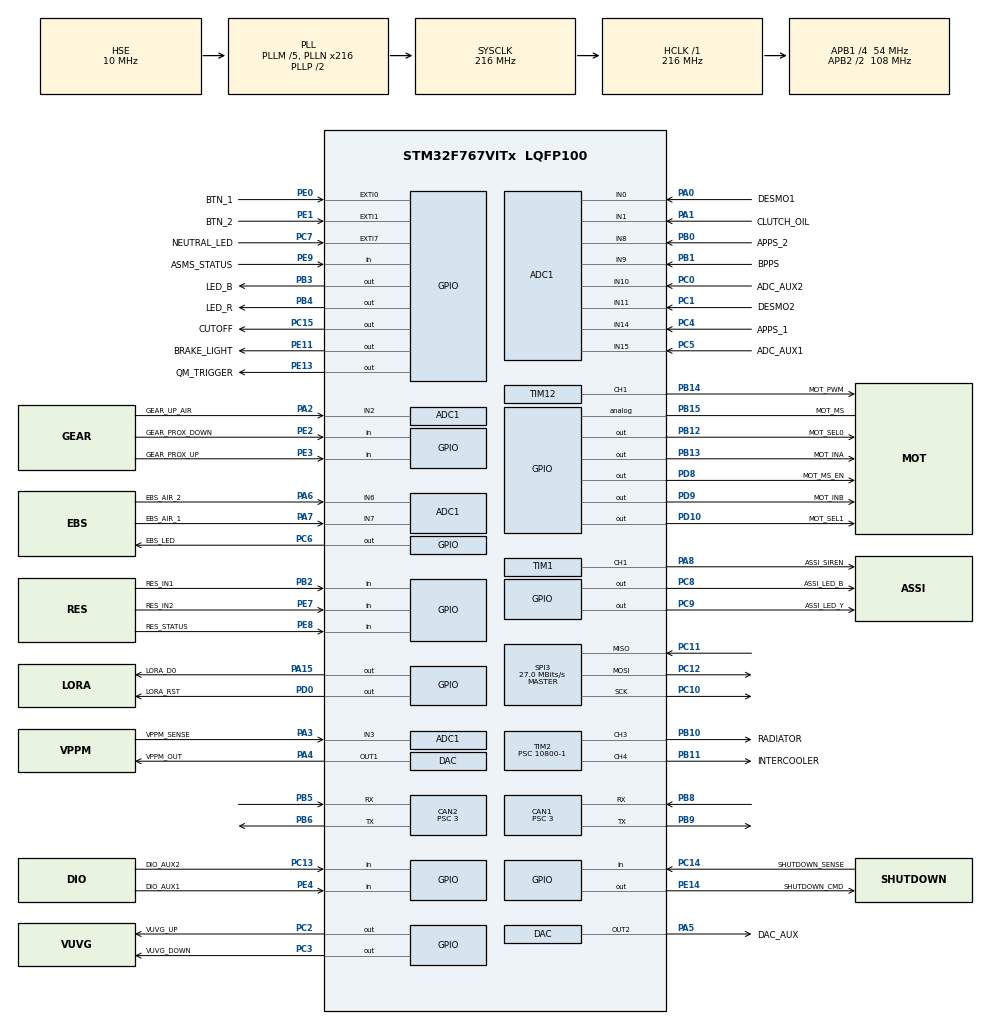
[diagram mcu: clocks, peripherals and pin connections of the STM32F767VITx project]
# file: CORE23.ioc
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ADC1.Channel-0\#ChannelRegularConversion=ADC_CHANNEL_0
ADC1.Channel-1\#ChannelRegularConversion=ADC_CHANNEL_1
ADC1.Channel-10\#ChannelRegularConversion=ADC_CHANNEL_14
ADC1.Channel-11\#ChannelRegularConversion=ADC_CHANNEL_15
ADC1.Channel-2\#ChannelRegularConversion=ADC_CHANNEL_2
ADC1.Channel-3\#ChannelRegularConversion=ADC_CHANNEL_3
ADC1.Channel-4\#ChannelRegularConversion=ADC_CHANNEL_6
ADC1.Channel-5\#ChannelRegularConversion=ADC_CHANNEL_7
ADC1.Channel-6\#ChannelRegularConversion=ADC_CHANNEL_8
ADC1.Channel-7\#ChannelRegularConversion=ADC_CHANNEL_9
ADC1.Channel-8\#ChannelRegularConversion=ADC_CHANNEL_10
ADC1.Channel-9\#ChannelRegularConversion=ADC_CHANNEL_11
ADC1.ContinuousConvMode=ENABLE
ADC1.DMAContinuousRequests=ENABLE
ADC1.EOCSelection=ADC_EOC_SINGLE_CONV
ADC1.NbrOfConversion=12
ADC1.NbrOfConversionFlag=1
ADC1.Rank-0\#ChannelRegularConversion=1
ADC1.Rank-1\#ChannelRegularConversion=2
ADC1.Rank-10\#ChannelRegularConversion=11
ADC1.Rank-11\#ChannelRegularConversion=12
ADC1.Rank-2\#ChannelRegularConversion=3
ADC1.Rank-3\#ChannelRegularConversion=4
ADC1.Rank-4\#ChannelRegularConversion=5
ADC1.Rank-5\#ChannelRegularConversion=6
ADC1.Rank-6\#ChannelRegularConversion=7
ADC1.Rank-7\#ChannelRegularConversion=8
ADC1.Rank-8\#ChannelRegularConversion=9
ADC1.Rank-9\#ChannelRegularConversion=10
ADC1.SamplingTime-0\#ChannelRegularConversion=ADC_SAMPLETIME_84CYCLES
ADC1.SamplingTime-1\#ChannelRegularConversion=ADC_SAMPLETIME_84CYCLES
ADC1.SamplingTime-10\#ChannelRegularConversion=ADC_SAMPLETIME_84CYCLES
ADC1.SamplingTime-11\#ChannelRegularConversion=ADC_SAMPLETIME_84CYCLES
ADC1.SamplingTime-2\#ChannelRegularConversion=ADC_SAMPLETIME_84CYCLES
ADC1.SamplingTime-3\#ChannelRegularConversion=ADC_SAMPLETIME_84CYCLES
ADC1.SamplingTime-4\#ChannelRegularConversion=ADC_SAMPLETIME_84CYCLES
ADC1.SamplingTime-5\#ChannelRegularConversion=ADC_SAMPLETIME_84CYCLES
ADC1.SamplingTime-6\#ChannelRegularConversion=ADC_SAMPLETIME_84CYCLES
ADC1.SamplingTime-7\#ChannelRegularConversion=ADC_SAMPLETIME_84CYCLES
ADC1.SamplingTime-8\#ChannelRegularConversion=ADC_SAMPLETIME_84CYCLES
ADC1.SamplingTime-9\#ChannelRegularConversion=ADC_SAMPLETIME_84CYCLES
ADC1.ScanConvMode=ADC_SCAN_ENABLE
ADC1.master=1
CAN1.BS1=CAN_BS1_15TQ
CAN1.BS2=CAN_BS2_2TQ
CAN1.CalculateBaudRate=1000000
CAN1.CalculateTimeBit=1000
CAN1.CalculateTimeQuantum=55.55555555555556
CAN1.Prescaler=3
CAN2.BS1=CAN_BS1_15TQ
CAN2.BS2=CAN_BS2_2TQ
CAN2.CalculateBaudRate=1000000
CAN2.CalculateTimeBit=1000
CAN2.CalculateTimeQuantum=55.55555555555556
CAN2.Prescaler=3
CAN2.RFLM=DISABLE
CAN2.SJW=CAN_SJW_1TQ
CORTEX_M7.CPU_DCache=Disabled
CORTEX_M7.CPU_ICache=Disabled
Dma.ADC1.0.Direction=DMA_PERIPH_TO_MEMORY
Dma.ADC1.0.FIFOMode=DMA_FIFOMODE_DISABLE
Dma.ADC1.0.Instance=DMA2_Stream0
Dma.ADC1.0.MemDataAlignment=DMA_MDATAALIGN_HALFWORD
Dma.ADC1.0.MemInc=DMA_MINC_ENABLE
Dma.ADC1.0.Mode=DMA_CIRCULAR
Dma.ADC1.0.PeriphDataAlignment=DMA_PDATAALIGN_HALFWORD
Dma.ADC1.0.PeriphInc=DMA_PINC_DISABLE
Dma.ADC1.0.Priority=DMA_PRIORITY_MEDIUM
Dma.Request0=ADC1
FREERTOS.Mutexes01=EngCanSem,Dynamic,NULL;ASCanSem,Dynamic,NULL;ADCSem,Dynamic,NULL;CanErrSem,Dynamic,NULL;ASBCheckSem,Dynamic,NULL
FREERTOS.Tasks01=FansContrTask,8,128,fansContrThread,As weak,NULL,Dynamic,NULL,NULL;DebugTask,8,128,debugThread,As weak,NULL,Dynamic,NULL,NULL;PedalTask,8,128,pedalThread,As weak,NULL,Dynamic,NULL,NULL;GearTask,8,128,gearThread,As weak,NULL,Dynamic,NULL,NULL;TelemetryTask,8,128,telemetryThread,As weak,NULL,Dynamic,NULL,NULL;ASAccTask,8,128,ASAccThread,As weak,NULL,Dynamic,NULL,NULL;ErrHandASTask,8,128,errorHandlerASThread,As weak,NULL,Dynamic,NULL,NULL;ASStateHandTask,8,128,ASStateHandlerThread,As weak,NULL,Dynamic,NULL,NULL;ASBCheckTask,8,128,ASBCheckThread,As weak,NULL,Dynamic,NULL,NULL;CheckModeTask,8,128,checkModeThread,As weak,NULL,Dynamic,NULL,NULL;CanHandlerTask,11,128,canHandlerThread,As weak,NULL,Dynamic,NULL,NULL;ADCTask,8,128,ADCThread,As weak,NULL,Dynamic,NULL,NULL
FREERTOS.configQUEUE_REGISTRY_SIZE=128
FREERTOS.configUSE_NEWLIB_REENTRANT=1
Mcu.Family=STM32F7
Mcu.Name=STM32F767VITx
Mcu.Package=LQFP100
NVIC.CAN1_RX0_IRQn=true\:5\:0\:false\:false\:true\:true\:true\:true\:true
NVIC.CAN2_RX1_IRQn=true\:5\:0\:false\:false\:true\:true\:true\:true\:true
NVIC.DMA2_Stream0_IRQn=true\:5\:0\:false\:false\:true\:true\:false\:true\:true
NVIC.EXTI0_IRQn=true\:5\:0\:false\:false\:true\:true\:true\:true\:true
NVIC.EXTI1_IRQn=true\:5\:0\:false\:false\:true\:true\:true\:true\:true
NVIC.EXTI9_5_IRQn=true\:5\:0\:false\:false\:true\:true\:true\:true\:true
NVIC.PriorityGroup=NVIC_PRIORITYGROUP_4
NVIC.TIM6_DAC_IRQn=true\:15\:0\:false\:false\:true\:false\:false\:true\:true
NVIC.TimeBase=TIM6_DAC_IRQn
NVIC.TimeBaseIP=TIM6
PA0/WKUP.GPIO_Label=DESMO1
PA0/WKUP.Signal=ADCx_IN0
PA1.GPIO_Label=CLUTCH_OIL
PA1.Signal=ADCx_IN1
PA13.Mode=Serial_Wire
PA13.Signal=SYS_JTMS-SWDIO
PA14.Mode=Serial_Wire
PA14.Signal=SYS_JTCK-SWCLK
PA15.GPIO_Label=LORA_D0
PA15.Signal=GPIO_Output
PA2.GPIO_Label=GEAR_UP_AIR
PA2.Signal=ADCx_IN2
PA3.GPIO_Label=VPPM_SENSE
PA3.Signal=ADCx_IN3
PA4.GPIO_Label=VPPM_OUT
PA4.Signal=COMP_DAC1_group
PA5.GPIO_Label=DAC_AUX
PA5.Signal=COMP_DAC2_group
PA6.GPIO_Label=EBS_AIR_2
PA6.Signal=ADCx_IN6
PA7.GPIO_Label=EBS_AIR_1
PA7.Signal=ADCx_IN7
PA8.GPIO_Label=ASSI_SIREN
PA8.Signal=S_TIM1_CH1
PB0.GPIO_Label=APPS_2
PB0.Signal=ADCx_IN8
PB1.GPIO_Label=BPPS
PB1.Signal=ADCx_IN9
PB10.GPIO_Label=RADIATOR
PB10.Signal=S_TIM2_CH3
PB11.GPIO_Label=INTERCOOLER
PB11.Signal=S_TIM2_CH4
PB12.GPIO_Label=MOT_SEL0
PB12.Signal=GPIO_Output
PB13.GPIO_Label=MOT_INA
PB13.Signal=GPIO_Output
PB14.GPIO_Label=MOT_PWM
PB14.Signal=S_TIM12_CH1
PB15.GPIO_Label=MOT_MS
PB15.Signal=GPIO_Analog
PB2.GPIO_Label=RES_IN1
PB2.Signal=GPIO_Input
PB3.GPIO_Label=LED_B
PB3.Signal=GPIO_Output
PB4.GPIO_Label=LED_R
PB4.Signal=GPIO_Output
PB5.Mode=CAN_Activate
PB5.Signal=CAN2_RX
PB6.Mode=CAN_Activate
PB6.Signal=CAN2_TX
PB8.Mode=CAN_Activate
PB8.Signal=CAN1_RX
PB9.Mode=CAN_Activate
PB9.Signal=CAN1_TX
PC0.GPIO_Label=ADC_AUX2
PC0.Signal=ADCx_IN10
PC1.GPIO_Label=DESMO2
PC1.Signal=ADCx_IN11
PC10.Mode=Full_Duplex_Master
PC10.Signal=SPI3_SCK
PC11.Mode=Full_Duplex_Master
PC11.Signal=SPI3_MISO
PC12.Mode=Full_Duplex_Master
PC12.Signal=SPI3_MOSI
PC13.GPIO_Label=DIO_AUX2
PC13.Signal=GPIO_Input
PC14/OSC32_IN.GPIO_Label=SHUTDOWN_SENSE
PC14/OSC32_IN.Signal=GPIO_Input
PC15/OSC32_OUT.GPIO_Label=CUTOFF
PC15/OSC32_OUT.Signal=GPIO_Output
PC2.GPIO_Label=VUVG_UP
PC2.Signal=GPIO_Output
PC3.GPIO_Label=VUVG_DOWN
PC3.Signal=GPIO_Output
PC4.GPIO_Label=APPS_1
PC4.Signal=ADCx_IN14
PC5.GPIO_Label=ADC_AUX1
PC5.Signal=ADCx_IN15
PC6.GPIO_Label=EBS_LED
PC6.Signal=GPIO_Output
PC7.GPIO_Label=NEUTRAL_LED
PC7.Signal=GPXTI7
PC8.GPIO_Label=ASSI_LED_B
PC8.Signal=GPIO_Output
PC9.GPIO_Label=ASSI_LED_Y
PC9.Signal=GPIO_Output
PD0.GPIO_Label=LORA_RST
PD0.Signal=GPIO_Output
PD10.GPIO_Label=MOT_SEL1
PD10.Signal=GPIO_Output
PD8.GPIO_Label=MOT_MS_EN
PD8.Signal=GPIO_Output
PD9.GPIO_Label=MOT_INB
PD9.Signal=GPIO_Output
PE0.GPIO_Label=BTN_1
PE0.GPIO_PuPd=GPIO_PULLDOWN
PE0.Signal=GPXTI0
PE1.GPIO_Label=BTN_2
PE1.GPIO_PuPd=GPIO_PULLDOWN
PE1.Signal=GPXTI1
PE11.GPIO_Label=BRAKE_LIGHT
PE11.Signal=GPIO_Output
PE13.GPIO_Label=QM_TRIGGER
PE13.GPIO_ModeDefaultOutputPP=GPIO_MODE_OUTPUT_PP
PE13.Signal=GPIO_Output
PE14.GPIO_Label=SHUTDOWN_CMD
PE14.Signal=GPIO_Output
PE2.GPIO_Label=GEAR_PROX_DOWN
PE2.Signal=GPIO_Input
PE3.GPIO_Label=GEAR_PROX_UP
PE3.Signal=GPIO_Input
PE4.GPIO_Label=DIO_AUX1
PE4.Signal=GPIO_Input
PE7.GPIO_Label=RES_IN2
PE7.Signal=GPIO_Input
PE8.GPIO_Label=RES_STATUS
PE8.Signal=GPIO_Input
PE9.GPIO_Label=ASMS_STATUS
PE9.Signal=GPIO_Input
PH0/OSC_IN.Mode=HSE-External-Oscillator
PH0/OSC_IN.Signal=RCC_OSC_IN
PH1/OSC_OUT.Mode=HSE-External-Oscillator
PH1/OSC_OUT.Signal=RCC_OSC_OUT
ProjectManager.HeapSize=0x200
ProjectManager.StackSize=0x400
ProjectManager.TargetToolchain=Makefile
RCC.AHBFreq_Value=216000000
RCC.APB1CLKDivider=RCC_HCLK_DIV4
RCC.APB1Freq_Value=54000000
RCC.APB1TimFreq_Value=108000000
RCC.APB2CLKDivider=RCC_HCLK_DIV2
RCC.APB2Freq_Value=108000000
RCC.APB2TimFreq_Value=216000000
RCC.CortexFreq_Value=216000000
RCC.HCLKFreq_Value=216000000
RCC.HSE_VALUE=10000000
RCC.HSI_VALUE=16000000
RCC.LSE_VALUE=32768
RCC.PLLM=5
RCC.PLLN=216
RCC.PLLSourceVirtual=RCC_PLLSOURCE_HSE
RCC.SYSCLKFreq_VALUE=216000000
RCC.SYSCLKSource=RCC_SYSCLKSOURCE_PLLCLK
RCC.USBFreq_Value=216000000
RCC.VCOOutputFreq_Value=432000000
SH.ADCx_IN0.0=ADC1_IN0,IN0
SH.ADCx_IN1.0=ADC1_IN1,IN1
SH.ADCx_IN10.0=ADC1_IN10,IN10
SH.ADCx_IN11.0=ADC1_IN11,IN11
SH.ADCx_IN14.0=ADC1_IN14,IN14
SH.ADCx_IN15.0=ADC1_IN15,IN15
SH.ADCx_IN2.0=ADC1_IN2,IN2
SH.ADCx_IN3.0=ADC1_IN3,IN3
SH.ADCx_IN6.0=ADC1_IN6,IN6
SH.ADCx_IN7.0=ADC1_IN7,IN7
SH.ADCx_IN8.0=ADC1_IN8,IN8
SH.ADCx_IN9.0=ADC1_IN9,IN9
SH.COMP_DAC1_group.0=DAC_OUT1,DAC_OUT1
SH.COMP_DAC2_group.0=DAC_OUT2,DAC_OUT2
SH.S_TIM12_CH1.0=TIM12_CH1,PWM Generation1 CH1
SH.S_TIM1_CH1.0=TIM1_CH1,PWM Generation1 CH1
SH.S_TIM2_CH3.0=TIM2_CH3,PWM Generation3 CH3
SH.S_TIM2_CH4.0=TIM2_CH4,PWM Generation4 CH4
SPI3.CalculateBaudRate=27.0 MBits/s
SPI3.Direction=SPI_DIRECTION_2LINES
SPI3.Mode=SPI_MODE_MASTER
SPI3.VirtualType=VM_MASTER
TIM1.Channel-PWM\ Generation1\ CH1=TIM_CHANNEL_1
TIM1.Period=100-1
TIM1.Prescaler=10800-1
TIM1.Pulse-PWM\ Generation1\ CH1=15
TIM12.Channel-PWM\ Generation1\ CH1=TIM_CHANNEL_1
TIM2.Channel-PWM\ Generation3\ CH3=TIM_CHANNEL_3
TIM2.Channel-PWM\ Generation4\ CH4=TIM_CHANNEL_4
TIM2.OCPolarity_3=TIM_OCPOLARITY_LOW
TIM2.OCPolarity_4=TIM_OCPOLARITY_LOW
TIM2.Period=100-1
TIM2.Prescaler=10800-1
TIM2.Pulse-PWM\ Generation3\ CH3=15
TIM2.Pulse-PWM\ Generation4\ CH4=15
TIM5.Prescaler=108
VP_FREERTOS_VS_CMSIS_V2.Mode=CMSIS_V2
VP_SYS_VS_tim6.Mode=TIM6
VP_TIM1_VS_ClockSourceINT.Mode=Internal
VP_TIM2_VS_ClockSourceINT.Mode=Internal
VP_TIM3_VS_ClockSourceINT.Mode=Internal
VP_TIM5_VS_ClockSourceINT.Mode=Internal
board=custom

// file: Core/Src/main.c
/* USER CODE BEGIN Header */
/**
  ******************************************************************************
  * @file           : main.c
  * @brief          : Main program body
  ******************************************************************************
  * @attention
  *
  * Copyright (c) 2024 STMicroelectronics.
  * All rights reserved.
  *
  * This software is licensed under terms that can be found in the LICENSE file
  * in the root directory of this software component.
  * If no LICENSE file comes with this software, it is provided AS-IS.
  *
  ******************************************************************************
  */
/* USER CODE END Header */
#include "main.h"
#include "cmsis_os.h"

ADC_HandleTypeDef hadc1;
DMA_HandleTypeDef hdma_adc1;

CAN_HandleTypeDef hcan1;
CAN_HandleTypeDef hcan2;

DAC_HandleTypeDef hdac;

SPI_HandleTypeDef hspi3;

TIM_HandleTypeDef htim1;
TIM_HandleTypeDef htim2;
TIM_HandleTypeDef htim3;
TIM_HandleTypeDef htim5;
TIM_HandleTypeDef htim12;

/* Definitions for FansContrTask */
osThreadId_t FansContrTaskHandle;
const osThreadAttr_t FansContrTask_attributes = {
  .name = "FansContrTask",
  .stack_size = 128 * 4,
  .priority = (osPriority_t) osPriorityLow,
};
/* Definitions for DebugTask */
osThreadId_t DebugTaskHandle;
const osThreadAttr_t DebugTask_attributes = {
  .name = "DebugTask",
  .stack_size = 128 * 4,
  .priority = (osPriority_t) osPriorityLow,
};
/* Definitions for PedalTask */
osThreadId_t PedalTaskHandle;
const osThreadAttr_t PedalTask_attributes = {
  .name = "PedalTask",
  .stack_size = 128 * 4,
  .priority = (osPriority_t) osPriorityLow,
};
/* Definitions for GearTask */
osThreadId_t GearTaskHandle;
const osThreadAttr_t GearTask_attributes = {
  .name = "GearTask",
  .stack_size = 128 * 4,
  .priority = (osPriority_t) osPriorityLow,
};
/* Definitions for TelemetryTask */
osThreadId_t TelemetryTaskHandle;
const osThreadAttr_t TelemetryTask_attributes = {
  .name = "TelemetryTask",
  .stack_size = 128 * 4,
  .priority = (osPriority_t) osPriorityLow,
};
/* Definitions for ASAccTask */
osThreadId_t ASAccTaskHandle;
const osThreadAttr_t ASAccTask_attributes = {
  .name = "ASAccTask",
  .stack_size = 128 * 4,
  .priority = (osPriority_t) osPriorityLow,
};
/* Definitions for ErrHandASTask */
osThreadId_t ErrHandASTaskHandle;
const osThreadAttr_t ErrHandASTask_attributes = {
  .name = "ErrHandASTask",
  .stack_size = 128 * 4,
  .priority = (osPriority_t) osPriorityLow,
};
/* Definitions for ASStateHandTask */
osThreadId_t ASStateHandTaskHandle;
const osThreadAttr_t ASStateHandTask_attributes = {
  .name = "ASStateHandTask",
  .stack_size = 128 * 4,
  .priority = (osPriority_t) osPriorityLow,
};
/* Definitions for ASBCheckTask */
osThreadId_t ASBCheckTaskHandle;
const osThreadAttr_t ASBCheckTask_attributes = {
  .name = "ASBCheckTask",
  .stack_size = 128 * 4,
  .priority = (osPriority_t) osPriorityLow,
};
/* Definitions for CheckModeTask */
osThreadId_t CheckModeTaskHandle;
const osThreadAttr_t CheckModeTask_attributes = {
  .name = "CheckModeTask",
  .stack_size = 128 * 4,
  .priority = (osPriority_t) osPriorityLow,
};
/* Definitions for CanHandlerTask */
osThreadId_t CanHandlerTaskHandle;
const osThreadAttr_t CanHandlerTask_attributes = {
  .name = "CanHandlerTask",
  .stack_size = 128 * 4,
  .priority = (osPriority_t) osPriorityLow3,
};
/* Definitions for ADCTask */
osThreadId_t ADCTaskHandle;
const osThreadAttr_t ADCTask_attributes = {
  .name = "ADCTask",
  .stack_size = 128 * 4,
  .priority = (osPriority_t) osPriorityLow,
};
/* Definitions for EngCanSem */
osMutexId_t EngCanSemHandle;
const osMutexAttr_t EngCanSem_attributes = {
  .name = "EngCanSem"
};
/* Definitions for ASCanSem */
osMutexId_t ASCanSemHandle;
const osMutexAttr_t ASCanSem_attributes = {
  .name = "ASCanSem"
};
/* Definitions for ADCSem */
osMutexId_t ADCSemHandle;
const osMutexAttr_t ADCSem_attributes = {
  .name = "ADCSem"
};
/* Definitions for CanErrSem */
osMutexId_t CanErrSemHandle;
const osMutexAttr_t CanErrSem_attributes = {
  .name = "CanErrSem"
};
/* Definitions for ASBCheckSem */
osMutexId_t ASBCheckSemHandle;
const osMutexAttr_t ASBCheckSem_attributes = {
  .name = "ASBCheckSem"
};

void SystemClock_Config(void);
static void MX_GPIO_Init(void);
static void MX_DMA_Init(void);
static void MX_CAN1_Init(void);
static void MX_CAN2_Init(void);
static void MX_DAC_Init(void);
static void MX_SPI3_Init(void);
static void MX_TIM1_Init(void);
static void MX_TIM2_Init(void);
static void MX_TIM3_Init(void);
static void MX_TIM12_Init(void);
static void MX_ADC1_Init(void);
static void MX_TIM5_Init(void);
void fansContrThread(void *argument);
void debugThread(void *argument);
void pedalThread(void *argument);
void gearThread(void *argument);
void telemetryThread(void *argument);
void ASAccThread(void *argument);
void errorHandlerASThread(void *argument);
void ASStateHandlerThread(void *argument);
void ASBCheckThread(void *argument);
void checkModeThread(void *argument);
void canHandlerThread(void *argument);
void ADCThread(void *argument);

int main(void)
{

  /* MCU Configuration--------------------------------------------------------*/

  /* Reset of all peripherals, Initializes the Flash interface and the Systick. */
  HAL_Init();

  /* Configure the system clock */
  SystemClock_Config();

  /* Initialize all configured peripherals */
  MX_GPIO_Init();
  MX_DMA_Init();
  MX_CAN1_Init();
  MX_CAN2_Init();
  MX_DAC_Init();
  MX_SPI3_Init();
  MX_TIM1_Init();
  MX_TIM2_Init();
  MX_TIM3_Init();
  MX_TIM12_Init();
  MX_ADC1_Init();
  MX_TIM5_Init();

  /* Init scheduler */
  osKernelInitialize();
  /* Create the mutex(es) */
  /* creation of EngCanSem */
  EngCanSemHandle = osMutexNew(&EngCanSem_attributes);

  /* creation of ASCanSem */
  ASCanSemHandle = osMutexNew(&ASCanSem_attributes);

  /* creation of ADCSem */
  ADCSemHandle = osMutexNew(&ADCSem_attributes);

  /* creation of CanErrSem */
  CanErrSemHandle = osMutexNew(&CanErrSem_attributes);

  /* creation of ASBCheckSem */
  ASBCheckSemHandle = osMutexNew(&ASBCheckSem_attributes);

  /* Create the thread(s) */
  /* creation of FansContrTask */
  FansContrTaskHandle = osThreadNew(fansContrThread, NULL, &FansContrTask_attributes);

  /* creation of DebugTask */
  DebugTaskHandle = osThreadNew(debugThread, NULL, &DebugTask_attributes);

  /* creation of PedalTask */
  PedalTaskHandle = osThreadNew(pedalThread, NULL, &PedalTask_attributes);

  /* creation of GearTask */
  GearTaskHandle = osThreadNew(gearThread, NULL, &GearTask_attributes);

  /* creation of TelemetryTask */
  TelemetryTaskHandle = osThreadNew(telemetryThread, NULL, &TelemetryTask_attributes);

  /* creation of ASAccTask */
  ASAccTaskHandle = osThreadNew(ASAccThread, NULL, &ASAccTask_attributes);

  /* creation of ErrHandASTask */
  ErrHandASTaskHandle = osThreadNew(errorHandlerASThread, NULL, &ErrHandASTask_attributes);

  /* creation of ASStateHandTask */
  ASStateHandTaskHandle = osThreadNew(ASStateHandlerThread, NULL, &ASStateHandTask_attributes);

  /* creation of ASBCheckTask */
  ASBCheckTaskHandle = osThreadNew(ASBCheckThread, NULL, &ASBCheckTask_attributes);

  /* creation of CheckModeTask */
  CheckModeTaskHandle = osThreadNew(checkModeThread, NULL, &CheckModeTask_attributes);

  /* creation of CanHandlerTask */
  CanHandlerTaskHandle = osThreadNew(canHandlerThread, NULL, &CanHandlerTask_attributes);

  /* creation of ADCTask */
  ADCTaskHandle = osThreadNew(ADCThread, NULL, &ADCTask_attributes);

  /* USER CODE BEGIN RTOS_THREADS */
  /* add threads, ... */
  // Always before kernel start, shutdown CMD should be always on
  HAL_GPIO_WritePin(SHUTDOWN_CMD_GPIO_Port, SHUTDOWN_CMD_Pin, SET);

  vTaskSuspend(ASStateHandTaskHandle);
  vTaskSuspend(ASBCheckTaskHandle);
  vTaskSuspend(TelemetryTaskHandle);
  vTaskSuspend(ErrHandASTaskHandle);
  vTaskSuspend(PedalTaskHandle);
  vTaskSuspend(GearTaskHandle);

  /* USER CODE END RTOS_THREADS */

  /* Start scheduler */
  osKernelStart();

  /* We should never get here as control is now taken by the scheduler */
  /* Infinite loop */
  while (1)
  {

  }
}

void SystemClock_Config(void)
{
  RCC_OscInitTypeDef RCC_OscInitStruct = {0};
  RCC_ClkInitTypeDef RCC_ClkInitStruct = {0};

  /** Configure the main internal regulator output voltage
  */
  __HAL_RCC_PWR_CLK_ENABLE();
  __HAL_PWR_VOLTAGESCALING_CONFIG(PWR_REGULATOR_VOLTAGE_SCALE1);

  /** Initializes the RCC Oscillators according to the specified parameters
  * in the RCC_OscInitTypeDef structure.
  */
  RCC_OscInitStruct.OscillatorType = RCC_OSCILLATORTYPE_HSE;
  RCC_OscInitStruct.HSEState = RCC_HSE_ON;
  RCC_OscInitStruct.PLL.PLLState = RCC_PLL_ON;
  RCC_OscInitStruct.PLL.PLLSource = RCC_PLLSOURCE_HSE;
  RCC_OscInitStruct.PLL.PLLM = 5;
  RCC_OscInitStruct.PLL.PLLN = 216;
  RCC_OscInitStruct.PLL.PLLP = RCC_PLLP_DIV2;
  RCC_OscInitStruct.PLL.PLLQ = 2;
  RCC_OscInitStruct.PLL.PLLR = 2;
  if (HAL_RCC_OscConfig(&RCC_OscInitStruct) != HAL_OK)
  {
    Error_Handler();
  }

  /** Activate the Over-Drive mode
  */
  if (HAL_PWREx_EnableOverDrive() != HAL_OK)
  {
    Error_Handler();
  }

  /** Initializes the CPU, AHB and APB buses clocks
  */
  RCC_ClkInitStruct.ClockType = RCC_CLOCKTYPE_HCLK|RCC_CLOCKTYPE_SYSCLK
                              |RCC_CLOCKTYPE_PCLK1|RCC_CLOCKTYPE_PCLK2;
  RCC_ClkInitStruct.SYSCLKSource = RCC_SYSCLKSOURCE_PLLCLK;
  RCC_ClkInitStruct.AHBCLKDivider = RCC_SYSCLK_DIV1;
  RCC_ClkInitStruct.APB1CLKDivider = RCC_HCLK_DIV4;
  RCC_ClkInitStruct.APB2CLKDivider = RCC_HCLK_DIV2;

  if (HAL_RCC_ClockConfig(&RCC_ClkInitStruct, FLASH_LATENCY_7) != HAL_OK)
  {
    Error_Handler();
  }
}

static void MX_ADC1_Init(void)
{

  ADC_ChannelConfTypeDef sConfig = {0};

  /** Configure the global features of the ADC (Clock, Resolution, Data Alignment and number of conversion)
  */
  hadc1.Instance = ADC1;
  hadc1.Init.ClockPrescaler = ADC_CLOCK_SYNC_PCLK_DIV4;
  hadc1.Init.Resolution = ADC_RESOLUTION_12B;
  hadc1.Init.ScanConvMode = ADC_SCAN_ENABLE;
  hadc1.Init.ContinuousConvMode = ENABLE;
  hadc1.Init.DiscontinuousConvMode = DISABLE;
  hadc1.Init.ExternalTrigConvEdge = ADC_EXTERNALTRIGCONVEDGE_NONE;
  hadc1.Init.ExternalTrigConv = ADC_SOFTWARE_START;
  hadc1.Init.DataAlign = ADC_DATAALIGN_RIGHT;
  hadc1.Init.NbrOfConversion = 12;
  hadc1.Init.DMAContinuousRequests = ENABLE;
  hadc1.Init.EOCSelection = ADC_EOC_SINGLE_CONV;
  if (HAL_ADC_Init(&hadc1) != HAL_OK)
  {
    Error_Handler();
  }

  /** Configure for the selected ADC regular channel its corresponding rank in the sequencer and its sample time.
  */
  sConfig.Channel = ADC_CHANNEL_0;
  sConfig.Rank = ADC_REGULAR_RANK_1;
  sConfig.SamplingTime = ADC_SAMPLETIME_84CYCLES;
  if (HAL_ADC_ConfigChannel(&hadc1, &sConfig) != HAL_OK)
  {
    Error_Handler();
  }

  /** Configure for the selected ADC regular channel its corresponding rank in the sequencer and its sample time.
  */
  sConfig.Channel = ADC_CHANNEL_1;
  sConfig.Rank = ADC_REGULAR_RANK_2;
  if (HAL_ADC_ConfigChannel(&hadc1, &sConfig) != HAL_OK)
  {
    Error_Handler();
  }

  /** Configure for the selected ADC regular channel its corresponding rank in the sequencer and its sample time.
  */
  sConfig.Channel = ADC_CHANNEL_2;
  sConfig.Rank = ADC_REGULAR_RANK_3;
  if (HAL_ADC_ConfigChannel(&hadc1, &sConfig) != HAL_OK)
  {
    Error_Handler();
  }

  /** Configure for the selected ADC regular channel its corresponding rank in the sequencer and its sample time.
  */
  sConfig.Channel = ADC_CHANNEL_3;
  sConfig.Rank = ADC_REGULAR_RANK_4;
  if (HAL_ADC_ConfigChannel(&hadc1, &sConfig) != HAL_OK)
  {
    Error_Handler();
  }

  /** Configure for the selected ADC regular channel its corresponding rank in the sequencer and its sample time.
  */
  sConfig.Channel = ADC_CHANNEL_6;
  sConfig.Rank = ADC_REGULAR_RANK_5;
  if (HAL_ADC_ConfigChannel(&hadc1, &sConfig) != HAL_OK)
  {
    Error_Handler();
  }

  /** Configure for the selected ADC regular channel its corresponding rank in the sequencer and its sample time.
  */
  sConfig.Channel = ADC_CHANNEL_7;
  sConfig.Rank = ADC_REGULAR_RANK_6;
  if (HAL_ADC_ConfigChannel(&hadc1, &sConfig) != HAL_OK)
  {
    Error_Handler();
  }

  /** Configure for the selected ADC regular channel its corresponding rank in the sequencer and its sample time.
  */
  sConfig.Channel = ADC_CHANNEL_8;
  sConfig.Rank = ADC_REGULAR_RANK_7;
  if (HAL_ADC_ConfigChannel(&hadc1, &sConfig) != HAL_OK)
  {
    Error_Handler();
  }

  /** Configure for the selected ADC regular channel its corresponding rank in the sequencer and its sample time.
  */
  sConfig.Channel = ADC_CHANNEL_9;
  sConfig.Rank = ADC_REGULAR_RANK_8;
  if (HAL_ADC_ConfigChannel(&hadc1, &sConfig) != HAL_OK)
  {
    Error_Handler();
  }

  /** Configure for the selected ADC regular channel its corresponding rank in the sequencer and its sample time.
  */
  sConfig.Channel = ADC_CHANNEL_10;
  sConfig.Rank = ADC_REGULAR_RANK_9;
  if (HAL_ADC_ConfigChannel(&hadc1, &sConfig) != HAL_OK)
  {
    Error_Handler();
  }

  /** Configure for the selected ADC regular channel its corresponding rank in the sequencer and its sample time.
  */
  sConfig.Channel = ADC_CHANNEL_11;
  sConfig.Rank = ADC_REGULAR_RANK_10;
  if (HAL_ADC_ConfigChannel(&hadc1, &sConfig) != HAL_OK)
  {
    Error_Handler();
  }

  /** Configure for the selected ADC regular channel its corresponding rank in the sequencer and its sample time.
  */
  sConfig.Channel = ADC_CHANNEL_14;
  sConfig.Rank = ADC_REGULAR_RANK_11;
  if (HAL_ADC_ConfigChannel(&hadc1, &sConfig) != HAL_OK)
  {
    Error_Handler();
  }

  /** Configure for the selected ADC regular channel its corresponding rank in the sequencer and its sample time.
  */
  sConfig.Channel = ADC_CHANNEL_15;
  sConfig.Rank = ADC_REGULAR_RANK_12;
  if (HAL_ADC_ConfigChannel(&hadc1, &sConfig) != HAL_OK)
  {
    Error_Handler();
  }

}

static void MX_CAN1_Init(void)
{

  hcan1.Instance = CAN1;
  hcan1.Init.Prescaler = 3;
  hcan1.Init.Mode = CAN_MODE_NORMAL;
  hcan1.Init.SyncJumpWidth = CAN_SJW_1TQ;
  hcan1.Init.TimeSeg1 = CAN_BS1_15TQ;
  hcan1.Init.TimeSeg2 = CAN_BS2_2TQ;
  hcan1.Init.TimeTriggeredMode = DISABLE;
  hcan1.Init.AutoBusOff = DISABLE;
  hcan1.Init.AutoWakeUp = DISABLE;
  hcan1.Init.AutoRetransmission = DISABLE;
  hcan1.Init.ReceiveFifoLocked = DISABLE;
  hcan1.Init.TransmitFifoPriority = DISABLE;
  if (HAL_CAN_Init(&hcan1) != HAL_OK)
  {
    Error_Handler();
  }

}

static void MX_CAN2_Init(void)
{

  hcan2.Instance = CAN2;
  hcan2.Init.Prescaler = 3;
  hcan2.Init.Mode = CAN_MODE_NORMAL;
  hcan2.Init.SyncJumpWidth = CAN_SJW_1TQ;
  hcan2.Init.TimeSeg1 = CAN_BS1_15TQ;
  hcan2.Init.TimeSeg2 = CAN_BS2_2TQ;
  hcan2.Init.TimeTriggeredMode = DISABLE;
  hcan2.Init.AutoBusOff = DISABLE;
  hcan2.Init.AutoWakeUp = DISABLE;
  hcan2.Init.AutoRetransmission = DISABLE;
  hcan2.Init.ReceiveFifoLocked = DISABLE;
  hcan2.Init.TransmitFifoPriority = DISABLE;
  if (HAL_CAN_Init(&hcan2) != HAL_OK)
  {
    Error_Handler();
  }

}

static void MX_DAC_Init(void)
{

  DAC_ChannelConfTypeDef sConfig = {0};

  /** DAC Initialization
  */
  hdac.Instance = DAC;
  if (HAL_DAC_Init(&hdac) != HAL_OK)
  {
    Error_Handler();
  }

  /** DAC channel OUT1 config
  */
  sConfig.DAC_Trigger = DAC_TRIGGER_NONE;
  sConfig.DAC_OutputBuffer = DAC_OUTPUTBUFFER_ENABLE;
  if (HAL_DAC_ConfigChannel(&hdac, &sConfig, DAC_CHANNEL_1) != HAL_OK)
  {
    Error_Handler();
  }

  /** DAC channel OUT2 config
  */
  if (HAL_DAC_ConfigChannel(&hdac, &sConfig, DAC_CHANNEL_2) != HAL_OK)
  {
    Error_Handler();
  }

}

static void MX_SPI3_Init(void)
{

  /* SPI3 parameter configuration*/
  hspi3.Instance = SPI3;
  hspi3.Init.Mode = SPI_MODE_MASTER;
  hspi3.Init.Direction = SPI_DIRECTION_2LINES;
  hspi3.Init.DataSize = SPI_DATASIZE_4BIT;
  hspi3.Init.CLKPolarity = SPI_POLARITY_LOW;
  hspi3.Init.CLKPhase = SPI_PHASE_1EDGE;
  hspi3.Init.NSS = SPI_NSS_SOFT;
  hspi3.Init.BaudRatePrescaler = SPI_BAUDRATEPRESCALER_2;
  hspi3.Init.FirstBit = SPI_FIRSTBIT_MSB;
  hspi3.Init.TIMode = SPI_TIMODE_DISABLE;
  hspi3.Init.CRCCalculation = SPI_CRCCALCULATION_DISABLE;
  hspi3.Init.CRCPolynomial = 7;
  hspi3.Init.CRCLength = SPI_CRC_LENGTH_DATASIZE;
  hspi3.Init.NSSPMode = SPI_NSS_PULSE_ENABLE;
  if (HAL_SPI_Init(&hspi3) != HAL_OK)
  {
    Error_Handler();
  }

}

static void MX_TIM1_Init(void)
{

  TIM_ClockConfigTypeDef sClockSourceConfig = {0};
  TIM_MasterConfigTypeDef sMasterConfig = {0};
  TIM_OC_InitTypeDef sConfigOC = {0};
  TIM_BreakDeadTimeConfigTypeDef sBreakDeadTimeConfig = {0};

  htim1.Instance = TIM1;
  htim1.Init.Prescaler = 10800-1;
  htim1.Init.CounterMode = TIM_COUNTERMODE_UP;
  htim1.Init.Period = 100-1;
  htim1.Init.ClockDivision = TIM_CLOCKDIVISION_DIV1;
  htim1.Init.RepetitionCounter = 0;
  htim1.Init.AutoReloadPreload = TIM_AUTORELOAD_PRELOAD_DISABLE;
  if (HAL_TIM_Base_Init(&htim1) != HAL_OK)
  {
    Error_Handler();
  }
  sClockSourceConfig.ClockSource = TIM_CLOCKSOURCE_INTERNAL;
  if (HAL_TIM_ConfigClockSource(&htim1, &sClockSourceConfig) != HAL_OK)
  {
    Error_Handler();
  }
  if (HAL_TIM_PWM_Init(&htim1) != HAL_OK)
  {
    Error_Handler();
  }
  sMasterConfig.MasterOutputTrigger = TIM_TRGO_RESET;
  sMasterConfig.MasterOutputTrigger2 = TIM_TRGO2_RESET;
  sMasterConfig.MasterSlaveMode = TIM_MASTERSLAVEMODE_DISABLE;
  if (HAL_TIMEx_MasterConfigSynchronization(&htim1, &sMasterConfig) != HAL_OK)
  {
    Error_Handler();
  }
  sConfigOC.OCMode = TIM_OCMODE_PWM1;
  sConfigOC.Pulse = 15;
  sConfigOC.OCPolarity = TIM_OCPOLARITY_HIGH;
  sConfigOC.OCNPolarity = TIM_OCNPOLARITY_HIGH;
  sConfigOC.OCFastMode = TIM_OCFAST_DISABLE;
  sConfigOC.OCIdleState = TIM_OCIDLESTATE_RESET;
  sConfigOC.OCNIdleState = TIM_OCNIDLESTATE_RESET;
  if (HAL_TIM_PWM_ConfigChannel(&htim1, &sConfigOC, TIM_CHANNEL_1) != HAL_OK)
  {
    Error_Handler();
  }
  sBreakDeadTimeConfig.OffStateRunMode = TIM_OSSR_DISABLE;
  sBreakDeadTimeConfig.OffStateIDLEMode = TIM_OSSI_DISABLE;
  sBreakDeadTimeConfig.LockLevel = TIM_LOCKLEVEL_OFF;
  sBreakDeadTimeConfig.DeadTime = 0;
  sBreakDeadTimeConfig.BreakState = TIM_BREAK_DISABLE;
  sBreakDeadTimeConfig.BreakPolarity = TIM_BREAKPOLARITY_HIGH;
  sBreakDeadTimeConfig.BreakFilter = 0;
  sBreakDeadTimeConfig.Break2State = TIM_BREAK2_DISABLE;
  sBreakDeadTimeConfig.Break2Polarity = TIM_BREAK2POLARITY_HIGH;
  sBreakDeadTimeConfig.Break2Filter = 0;
  sBreakDeadTimeConfig.AutomaticOutput = TIM_AUTOMATICOUTPUT_DISABLE;
  if (HAL_TIMEx_ConfigBreakDeadTime(&htim1, &sBreakDeadTimeConfig) != HAL_OK)
  {
    Error_Handler();
  }
  HAL_TIM_MspPostInit(&htim1);

}

static void MX_TIM2_Init(void)
{

  TIM_ClockConfigTypeDef sClockSourceConfig = {0};
  TIM_MasterConfigTypeDef sMasterConfig = {0};
  TIM_OC_InitTypeDef sConfigOC = {0};

  htim2.Instance = TIM2;
  htim2.Init.Prescaler = 10800-1;
  htim2.Init.CounterMode = TIM_COUNTERMODE_UP;
  htim2.Init.Period = 100-1;
  htim2.Init.ClockDivision = TIM_CLOCKDIVISION_DIV1;
  htim2.Init.AutoReloadPreload = TIM_AUTORELOAD_PRELOAD_DISABLE;
  if (HAL_TIM_Base_Init(&htim2) != HAL_OK)
  {
    Error_Handler();
  }
  sClockSourceConfig.ClockSource = TIM_CLOCKSOURCE_INTERNAL;
  if (HAL_TIM_ConfigClockSource(&htim2, &sClockSourceConfig) != HAL_OK)
  {
    Error_Handler();
  }
  if (HAL_TIM_PWM_Init(&htim2) != HAL_OK)
  {
    Error_Handler();
  }
  sMasterConfig.MasterOutputTrigger = TIM_TRGO_RESET;
  sMasterConfig.MasterSlaveMode = TIM_MASTERSLAVEMODE_DISABLE;
  if (HAL_TIMEx_MasterConfigSynchronization(&htim2, &sMasterConfig) != HAL_OK)
  {
    Error_Handler();
  }
  sConfigOC.OCMode = TIM_OCMODE_PWM1;
  sConfigOC.Pulse = 15;
  sConfigOC.OCPolarity = TIM_OCPOLARITY_LOW;
  sConfigOC.OCFastMode = TIM_OCFAST_DISABLE;
  if (HAL_TIM_PWM_ConfigChannel(&htim2, &sConfigOC, TIM_CHANNEL_3) != HAL_OK)
  {
    Error_Handler();
  }
  if (HAL_TIM_PWM_ConfigChannel(&htim2, &sConfigOC, TIM_CHANNEL_4) != HAL_OK)
  {
    Error_Handler();
  }
  HAL_TIM_MspPostInit(&htim2);

}

static void MX_TIM3_Init(void)
{

  TIM_ClockConfigTypeDef sClockSourceConfig = {0};
  TIM_MasterConfigTypeDef sMasterConfig = {0};

  htim3.Instance = TIM3;
  htim3.Init.Prescaler = 0;
  htim3.Init.CounterMode = TIM_COUNTERMODE_UP;
  htim3.Init.Period = 65535;
  htim3.Init.ClockDivision = TIM_CLOCKDIVISION_DIV1;
  htim3.Init.AutoReloadPreload = TIM_AUTORELOAD_PRELOAD_DISABLE;
  if (HAL_TIM_Base_Init(&htim3) != HAL_OK)
  {
    Error_Handler();
  }
  sClockSourceConfig.ClockSource = TIM_CLOCKSOURCE_INTERNAL;
  if (HAL_TIM_ConfigClockSource(&htim3, &sClockSourceConfig) != HAL_OK)
  {
    Error_Handler();
  }
  sMasterConfig.MasterOutputTrigger = TIM_TRGO_RESET;
  sMasterConfig.MasterSlaveMode = TIM_MASTERSLAVEMODE_DISABLE;
  if (HAL_TIMEx_MasterConfigSynchronization(&htim3, &sMasterConfig) != HAL_OK)
  {
    Error_Handler();
  }

}

static void MX_TIM5_Init(void)
{

  TIM_ClockConfigTypeDef sClockSourceConfig = {0};
  TIM_MasterConfigTypeDef sMasterConfig = {0};

  htim5.Instance = TIM5;
  htim5.Init.Prescaler = 108;
  htim5.Init.CounterMode = TIM_COUNTERMODE_UP;
  htim5.Init.Period = 4294967295;
  htim5.Init.ClockDivision = TIM_CLOCKDIVISION_DIV1;
  htim5.Init.AutoReloadPreload = TIM_AUTORELOAD_PRELOAD_DISABLE;
  if (HAL_TIM_Base_Init(&htim5) != HAL_OK)
  {
    Error_Handler();
  }
  sClockSourceConfig.ClockSource = TIM_CLOCKSOURCE_INTERNAL;
  if (HAL_TIM_ConfigClockSource(&htim5, &sClockSourceConfig) != HAL_OK)
  {
    Error_Handler();
  }
  sMasterConfig.MasterOutputTrigger = TIM_TRGO_RESET;
  sMasterConfig.MasterSlaveMode = TIM_MASTERSLAVEMODE_DISABLE;
  if (HAL_TIMEx_MasterConfigSynchronization(&htim5, &sMasterConfig) != HAL_OK)
  {
    Error_Handler();
  }

}

static void MX_TIM12_Init(void)
{

  TIM_OC_InitTypeDef sConfigOC = {0};

  htim12.Instance = TIM12;
  htim12.Init.Prescaler = 0;
  htim12.Init.CounterMode = TIM_COUNTERMODE_UP;
  htim12.Init.Period = 65535;
  htim12.Init.ClockDivision = TIM_CLOCKDIVISION_DIV1;
  htim12.Init.AutoReloadPreload = TIM_AUTORELOAD_PRELOAD_DISABLE;
  if (HAL_TIM_PWM_Init(&htim12) != HAL_OK)
  {
    Error_Handler();
  }
  sConfigOC.OCMode = TIM_OCMODE_PWM1;
  sConfigOC.Pulse = 0;
  sConfigOC.OCPolarity = TIM_OCPOLARITY_HIGH;
  sConfigOC.OCFastMode = TIM_OCFAST_DISABLE;
  if (HAL_TIM_PWM_ConfigChannel(&htim12, &sConfigOC, TIM_CHANNEL_1) != HAL_OK)
  {
    Error_Handler();
  }
  HAL_TIM_MspPostInit(&htim12);

}

static void MX_DMA_Init(void)
{

  /* DMA controller clock enable */
  __HAL_RCC_DMA2_CLK_ENABLE();

  /* DMA interrupt init */
  /* DMA2_Stream0_IRQn interrupt configuration */
  HAL_NVIC_SetPriority(DMA2_Stream0_IRQn, 5, 0);
  HAL_NVIC_EnableIRQ(DMA2_Stream0_IRQn);

}

static void MX_GPIO_Init(void)
{
  GPIO_InitTypeDef GPIO_InitStruct = {0};

  /* GPIO Ports Clock Enable */
  __HAL_RCC_GPIOE_CLK_ENABLE();
  __HAL_RCC_GPIOC_CLK_ENABLE();
  __HAL_RCC_GPIOH_CLK_ENABLE();
  __HAL_RCC_GPIOA_CLK_ENABLE();
  __HAL_RCC_GPIOB_CLK_ENABLE();
  __HAL_RCC_GPIOD_CLK_ENABLE();

  /*Configure GPIO pin Output Level */
  HAL_GPIO_WritePin(GPIOC, CUTOFF_Pin|VUVG_UP_Pin|VUVG_DOWN_Pin|EBS_LED_Pin
                          |ASSI_LED_B_Pin|ASSI_LED_Y_Pin, GPIO_PIN_RESET);

  /*Configure GPIO pin Output Level */
  HAL_GPIO_WritePin(GPIOE, BRAKE_LIGHT_Pin|QM_TRIGGER_Pin|SHUTDOWN_CMD_Pin, GPIO_PIN_RESET);

  /*Configure GPIO pin Output Level */
  HAL_GPIO_WritePin(GPIOB, MOT_SEL0_Pin|MOT_INA_Pin|LED_B_Pin|LED_R_Pin, GPIO_PIN_RESET);

  /*Configure GPIO pin Output Level */
  HAL_GPIO_WritePin(GPIOD, MOT_MS_EN_Pin|MOT_INB_Pin|MOT_SEL1_Pin|LORA_RST_Pin, GPIO_PIN_RESET);

  /*Configure GPIO pin Output Level */
  HAL_GPIO_WritePin(LORA_D0_GPIO_Port, LORA_D0_Pin, GPIO_PIN_RESET);

  /*Configure GPIO pins : GEAR_PROX_DOWN_Pin GEAR_PROX_UP_Pin DIO_AUX1_Pin RES_IN2_Pin
                           RES_STATUS_Pin ASMS_STATUS_Pin */
  GPIO_InitStruct.Pin = GEAR_PROX_DOWN_Pin|GEAR_PROX_UP_Pin|DIO_AUX1_Pin|RES_IN2_Pin
                          |RES_STATUS_Pin|ASMS_STATUS_Pin;
  GPIO_InitStruct.Mode = GPIO_MODE_INPUT;
  GPIO_InitStruct.Pull = GPIO_NOPULL;
  HAL_GPIO_Init(GPIOE, &GPIO_InitStruct);

  /*Configure GPIO pins : DIO_AUX2_Pin SHUTDOWN_SENSE_Pin */
  GPIO_InitStruct.Pin = DIO_AUX2_Pin|SHUTDOWN_SENSE_Pin;
  GPIO_InitStruct.Mode = GPIO_MODE_INPUT;
  GPIO_InitStruct.Pull = GPIO_NOPULL;
  HAL_GPIO_Init(GPIOC, &GPIO_InitStruct);

  /*Configure GPIO pins : CUTOFF_Pin VUVG_UP_Pin VUVG_DOWN_Pin EBS_LED_Pin
                           ASSI_LED_B_Pin ASSI_LED_Y_Pin */
  GPIO_InitStruct.Pin = CUTOFF_Pin|VUVG_UP_Pin|VUVG_DOWN_Pin|EBS_LED_Pin
                          |ASSI_LED_B_Pin|ASSI_LED_Y_Pin;
  GPIO_InitStruct.Mode = GPIO_MODE_OUTPUT_PP;
  GPIO_InitStruct.Pull = GPIO_NOPULL;
  GPIO_InitStruct.Speed = GPIO_SPEED_FREQ_LOW;
  HAL_GPIO_Init(GPIOC, &GPIO_InitStruct);

  /*Configure GPIO pin : RES_IN1_Pin */
  GPIO_InitStruct.Pin = RES_IN1_Pin;
  GPIO_InitStruct.Mode = GPIO_MODE_INPUT;
  GPIO_InitStruct.Pull = GPIO_NOPULL;
  HAL_GPIO_Init(RES_IN1_GPIO_Port, &GPIO_InitStruct);

  /*Configure GPIO pins : BRAKE_LIGHT_Pin QM_TRIGGER_Pin SHUTDOWN_CMD_Pin */
  GPIO_InitStruct.Pin = BRAKE_LIGHT_Pin|QM_TRIGGER_Pin|SHUTDOWN_CMD_Pin;
  GPIO_InitStruct.Mode = GPIO_MODE_OUTPUT_PP;
  GPIO_InitStruct.Pull = GPIO_NOPULL;
  GPIO_InitStruct.Speed = GPIO_SPEED_FREQ_LOW;
  HAL_GPIO_Init(GPIOE, &GPIO_InitStruct);

  /*Configure GPIO pins : MOT_SEL0_Pin MOT_INA_Pin LED_B_Pin LED_R_Pin */
  GPIO_InitStruct.Pin = MOT_SEL0_Pin|MOT_INA_Pin|LED_B_Pin|LED_R_Pin;
  GPIO_InitStruct.Mode = GPIO_MODE_OUTPUT_PP;
  GPIO_InitStruct.Pull = GPIO_NOPULL;
  GPIO_InitStruct.Speed = GPIO_SPEED_FREQ_LOW;
  HAL_GPIO_Init(GPIOB, &GPIO_InitStruct);

  /*Configure GPIO pin : MOT_MS_Pin */
  GPIO_InitStruct.Pin = MOT_MS_Pin;
  GPIO_InitStruct.Mode = GPIO_MODE_ANALOG;
  GPIO_InitStruct.Pull = GPIO_NOPULL;
  HAL_GPIO_Init(MOT_MS_GPIO_Port, &GPIO_InitStruct);

  /*Configure GPIO pins : MOT_MS_EN_Pin MOT_INB_Pin MOT_SEL1_Pin LORA_RST_Pin */
  GPIO_InitStruct.Pin = MOT_MS_EN_Pin|MOT_INB_Pin|MOT_SEL1_Pin|LORA_RST_Pin;
  GPIO_InitStruct.Mode = GPIO_MODE_OUTPUT_PP;
  GPIO_InitStruct.Pull = GPIO_NOPULL;
  GPIO_InitStruct.Speed = GPIO_SPEED_FREQ_LOW;
  HAL_GPIO_Init(GPIOD, &GPIO_InitStruct);

  /*Configure GPIO pin : NEUTRAL_LED_Pin */
  GPIO_InitStruct.Pin = NEUTRAL_LED_Pin;
  GPIO_InitStruct.Mode = GPIO_MODE_IT_RISING;
  GPIO_InitStruct.Pull = GPIO_NOPULL;
  HAL_GPIO_Init(NEUTRAL_LED_GPIO_Port, &GPIO_InitStruct);

  /*Configure GPIO pin : LORA_D0_Pin */
  GPIO_InitStruct.Pin = LORA_D0_Pin;
  GPIO_InitStruct.Mode = GPIO_MODE_OUTPUT_PP;
  GPIO_InitStruct.Pull = GPIO_NOPULL;
  GPIO_InitStruct.Speed = GPIO_SPEED_FREQ_LOW;
  HAL_GPIO_Init(LORA_D0_GPIO_Port, &GPIO_InitStruct);

  /*Configure GPIO pins : BTN_1_Pin BTN_2_Pin */
  GPIO_InitStruct.Pin = BTN_1_Pin|BTN_2_Pin;
  GPIO_InitStruct.Mode = GPIO_MODE_IT_RISING;
  GPIO_InitStruct.Pull = GPIO_PULLDOWN;
  HAL_GPIO_Init(GPIOE, &GPIO_InitStruct);

  /* EXTI interrupt init*/
  HAL_NVIC_SetPriority(EXTI0_IRQn, 5, 0);
  HAL_NVIC_EnableIRQ(EXTI0_IRQn);

  HAL_NVIC_SetPriority(EXTI1_IRQn, 5, 0);
  HAL_NVIC_EnableIRQ(EXTI1_IRQn);

  HAL_NVIC_SetPriority(EXTI9_5_IRQn, 5, 0);
  HAL_NVIC_EnableIRQ(EXTI9_5_IRQn);

}

__weak void fansContrThread(void *argument)
{
  for(;;)
  {
    osDelay(1);
  }
}

__weak void debugThread(void *argument)
{
  for(;;)
  {
    osDelay(1);
  }
}

__weak void pedalThread(void *argument)
{
  for(;;)
  {
    osDelay(1);
  }
}

__weak void gearThread(void *argument)
{
  for(;;)
  {
    osDelay(1);
  }
}

__weak void telemetryThread(void *argument)
{
  for(;;)
  {
    osDelay(1);
  }
}

__weak void ASAccThread(void *argument)
{
  for(;;)
  {
    osDelay(1);
  }
}

__weak void errorHandlerASThread(void *argument)
{
  for(;;)
  {
    osDelay(1);
  }
}

__weak void ASStateHandlerThread(void *argument)
{
  for(;;)
  {
    osDelay(1);
  }
}

__weak void ASBCheckThread(void *argument)
{
  for(;;)
  {
    osDelay(1);
  }
}

__weak void checkModeThread(void *argument)
{
  for(;;)
  {
    osDelay(1);
  }
}

__weak void canHandlerThread(void *argument)
{
  for(;;)
  {
    osDelay(1);
  }
}

__weak void ADCThread(void *argument)
{
  for(;;)
  {
    osDelay(1);
  }
}

void HAL_TIM_PeriodElapsedCallback(TIM_HandleTypeDef *htim)
{
  if (htim->Instance == TIM6) {
    HAL_IncTick();
  }
}

void Error_Handler(void)
{
  __disable_irq();
  while (1)
  {
  }
}

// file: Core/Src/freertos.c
/* USER CODE BEGIN Header */
/**
  ******************************************************************************
  * File Name          : freertos.c
  * Description        : Code for freertos applications
  ******************************************************************************
  * @attention
  *
  * Copyright (c) 2024 STMicroelectronics.
  * All rights reserved.
  *
  * This software is licensed under terms that can be found in the LICENSE file
  * in the root directory of this software component.
  * If no LICENSE file comes with this software, it is provided AS-IS.
  *
  ******************************************************************************
  */
/* USER CODE END Header */

#include "FreeRTOS.h"
#include "task.h"
#include "main.h"
#include "cmsis_os.h"

/* Definitions for fansTask */
osThreadId_t fansTaskHandle;
const osThreadAttr_t fansTask_attributes = {
  .name = "fansTask",
  .stack_size = 128 * 4,
  .priority = (osPriority_t) osPriorityLow,
};
/* Definitions for debugTask */
osThreadId_t debugTaskHandle;
const osThreadAttr_t debugTask_attributes = {
  .name = "debugTask",
  .stack_size = 128 * 4,
  .priority = (osPriority_t) osPriorityLow,
};
/* Definitions for pedalsTask */
osThreadId_t pedalsTaskHandle;
const osThreadAttr_t pedalsTask_attributes = {
  .name = "pedalsTask",
  .stack_size = 128 * 4,
  .priority = (osPriority_t) osPriorityLow,
};
/* Definitions for gearTask */
osThreadId_t gearTaskHandle;
const osThreadAttr_t gearTask_attributes = {
  .name = "gearTask",
  .stack_size = 128 * 4,
  .priority = (osPriority_t) osPriorityLow,
};
/* Definitions for telemetryTask */
osThreadId_t telemetryTaskHandle;
const osThreadAttr_t telemetryTask_attributes = {
  .name = "telemetryTask",
  .stack_size = 128 * 4,
  .priority = (osPriority_t) osPriorityLow,
};

void fans_thread(void *argument);
void debug_thread(void *argument);
void pedals_thread(void *argument);
void gear_thread(void *argument);
void telemetry_thread(void *argument);

void MX_FREERTOS_Init(void); /* (MISRA C 2004 rule 8.1) */

void MX_FREERTOS_Init(void) {

  /* Create the thread(s) */
  /* creation of fansTask */
  fansTaskHandle = osThreadNew(fans_thread, NULL, &fansTask_attributes);

  /* creation of debugTask */
  debugTaskHandle = osThreadNew(debug_thread, NULL, &debugTask_attributes);

  /* creation of pedalsTask */
  pedalsTaskHandle = osThreadNew(pedals_thread, NULL, &pedalsTask_attributes);

  /* creation of gearTask */
  gearTaskHandle = osThreadNew(gear_thread, NULL, &gearTask_attributes);

  /* creation of telemetryTask */
  telemetryTaskHandle = osThreadNew(telemetry_thread, NULL, &telemetryTask_attributes);

}

__weak void fans_thread(void *argument)
{
  for(;;)
  {
    osDelay(1);
  }
}

__weak void debug_thread(void *argument)
{
  for(;;)
  {
    osDelay(1);
  }
}

__weak void pedals_thread(void *argument)
{
  for(;;)
  {
    osDelay(1);
  }
}

__weak void gear_thread(void *argument)
{
  for(;;)
  {
    osDelay(1);
  }
}

__weak void telemetry_thread(void *argument)
{
  for(;;)
  {
    osDelay(1);
  }
}
